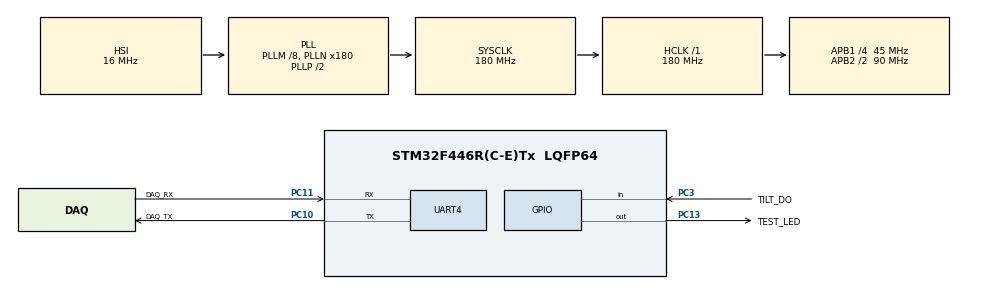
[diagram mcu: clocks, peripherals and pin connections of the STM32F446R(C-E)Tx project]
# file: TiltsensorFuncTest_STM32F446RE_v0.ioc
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Mcu.Family=STM32F4
Mcu.Name=STM32F446R(C-E)Tx
Mcu.Package=LQFP64
NVIC.PriorityGroup=NVIC_PRIORITYGROUP_4
PC10.GPIO_Label=DAQ_TX
PC10.Mode=Asynchronous
PC10.Signal=UART4_TX
PC11.GPIO_Label=DAQ_RX
PC11.Mode=Asynchronous
PC11.Signal=UART4_RX
PC13.GPIO_Label=TEST_LED
PC13.GPIO_PuPd=GPIO_PULLDOWN
PC13.Signal=GPIO_Output
PC14-OSC32_IN.Mode=LSE-External-Oscillator
PC14-OSC32_IN.Signal=RCC_OSC32_IN
PC15-OSC32_OUT.Mode=LSE-External-Oscillator
PC15-OSC32_OUT.Signal=RCC_OSC32_OUT
PC3.GPIO_Label=TILT_DO
PC3.Signal=GPIO_Input
PH0-OSC_IN.Mode=HSE-External-Oscillator
PH0-OSC_IN.Signal=RCC_OSC_IN
PH1-OSC_OUT.Mode=HSE-External-Oscillator
PH1-OSC_OUT.Signal=RCC_OSC_OUT
ProjectManager.HeapSize=0x200
ProjectManager.StackSize=0x400
ProjectManager.TargetToolchain=STM32CubeIDE
RCC.AHBFreq_Value=180000000
RCC.APB1CLKDivider=RCC_HCLK_DIV4
RCC.APB1Freq_Value=45000000
RCC.APB1TimFreq_Value=90000000
RCC.APB2CLKDivider=RCC_HCLK_DIV2
RCC.APB2Freq_Value=90000000
RCC.APB2TimFreq_Value=180000000
RCC.CortexFreq_Value=180000000
RCC.HCLKFreq_Value=180000000
RCC.PLLM=8
RCC.PLLN=180
RCC.SYSCLKFreq_VALUE=180000000
RCC.SYSCLKSource=RCC_SYSCLKSOURCE_PLLCLK
RCC.USBFreq_Value=180000000
RCC.VCOOutputFreq_Value=360000000
UART4.VirtualMode=Asynchronous
board=custom

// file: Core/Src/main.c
/* USER CODE BEGIN Header */
/**
  ******************************************************************************
  * @file           : main.c
  * @brief          : Main program body
  ******************************************************************************
  * @attention
  *
  * Copyright (c) 2024 STMicroelectronics.
  * All rights reserved.
  *
  * This software is licensed under terms that can be found in the LICENSE file
  * in the root directory of this software component.
  * If no LICENSE file comes with this software, it is provided AS-IS.
  *
  ******************************************************************************
  */
/* USER CODE END Header */
#include "main.h"

/* USER CODE BEGIN Includes */
#include "stdbool.h"
#include "string.h"
/* USER CODE END Includes */

UART_HandleTypeDef huart4;

/* USER CODE BEGIN PV */
bool tilt_state = 0;
/* USER CODE END PV */

void SystemClock_Config(void);
static void MX_GPIO_Init(void);
static void MX_UART4_Init(void);

int main(void)
{

  /* MCU Configuration--------------------------------------------------------*/

  /* Reset of all peripherals, Initializes the Flash interface and the Systick. */
  HAL_Init();

  /* Configure the system clock */
  SystemClock_Config();

  /* Initialize all configured peripherals */
  MX_GPIO_Init();
  MX_UART4_Init();

  /* Infinite loop */
  while (1)
  {

    /* USER CODE BEGIN 3 */
	  tilt_state = !HAL_GPIO_ReadPin(TILT_DO_GPIO_Port, TILT_DO_Pin);
	  if(tilt_state)
		  HAL_GPIO_WritePin(TEST_LED_GPIO_Port, TEST_LED_Pin, 1);
	  else
		  HAL_GPIO_WritePin(TEST_LED_GPIO_Port, TEST_LED_Pin, 1);

	  char buffer[10]={0};
	  memcpy(&buffer,&tilt_state,1);
	  HAL_UART_Transmit(&huart4, &buffer, 1, 100);
	  HAL_Delay(10);
  }
  /* USER CODE END 3 */
}

void SystemClock_Config(void)
{
  RCC_OscInitTypeDef RCC_OscInitStruct = {0};
  RCC_ClkInitTypeDef RCC_ClkInitStruct = {0};

  /** Configure the main internal regulator output voltage
  */
  __HAL_RCC_PWR_CLK_ENABLE();
  __HAL_PWR_VOLTAGESCALING_CONFIG(PWR_REGULATOR_VOLTAGE_SCALE1);

  /** Initializes the RCC Oscillators according to the specified parameters
  * in the RCC_OscInitTypeDef structure.
  */
  RCC_OscInitStruct.OscillatorType = RCC_OSCILLATORTYPE_HSI;
  RCC_OscInitStruct.HSIState = RCC_HSI_ON;
  RCC_OscInitStruct.HSICalibrationValue = RCC_HSICALIBRATION_DEFAULT;
  RCC_OscInitStruct.PLL.PLLState = RCC_PLL_ON;
  RCC_OscInitStruct.PLL.PLLSource = RCC_PLLSOURCE_HSI;
  RCC_OscInitStruct.PLL.PLLM = 8;
  RCC_OscInitStruct.PLL.PLLN = 180;
  RCC_OscInitStruct.PLL.PLLP = RCC_PLLP_DIV2;
  RCC_OscInitStruct.PLL.PLLQ = 2;
  RCC_OscInitStruct.PLL.PLLR = 2;
  if (HAL_RCC_OscConfig(&RCC_OscInitStruct) != HAL_OK)
  {
    Error_Handler();
  }

  /** Activate the Over-Drive mode
  */
  if (HAL_PWREx_EnableOverDrive() != HAL_OK)
  {
    Error_Handler();
  }

  /** Initializes the CPU, AHB and APB buses clocks
  */
  RCC_ClkInitStruct.ClockType = RCC_CLOCKTYPE_HCLK|RCC_CLOCKTYPE_SYSCLK
                              |RCC_CLOCKTYPE_PCLK1|RCC_CLOCKTYPE_PCLK2;
  RCC_ClkInitStruct.SYSCLKSource = RCC_SYSCLKSOURCE_PLLCLK;
  RCC_ClkInitStruct.AHBCLKDivider = RCC_SYSCLK_DIV1;
  RCC_ClkInitStruct.APB1CLKDivider = RCC_HCLK_DIV4;
  RCC_ClkInitStruct.APB2CLKDivider = RCC_HCLK_DIV2;

  if (HAL_RCC_ClockConfig(&RCC_ClkInitStruct, FLASH_LATENCY_5) != HAL_OK)
  {
    Error_Handler();
  }
}

static void MX_UART4_Init(void)
{

  huart4.Instance = UART4;
  huart4.Init.BaudRate = 115200;
  huart4.Init.WordLength = UART_WORDLENGTH_8B;
  huart4.Init.StopBits = UART_STOPBITS_1;
  huart4.Init.Parity = UART_PARITY_NONE;
  huart4.Init.Mode = UART_MODE_TX_RX;
  huart4.Init.HwFlowCtl = UART_HWCONTROL_NONE;
  huart4.Init.OverSampling = UART_OVERSAMPLING_16;
  if (HAL_UART_Init(&huart4) != HAL_OK)
  {
    Error_Handler();
  }

}

static void MX_GPIO_Init(void)
{
  GPIO_InitTypeDef GPIO_InitStruct = {0};

  /* GPIO Ports Clock Enable */
  __HAL_RCC_GPIOC_CLK_ENABLE();
  __HAL_RCC_GPIOH_CLK_ENABLE();

  /*Configure GPIO pin Output Level */
  HAL_GPIO_WritePin(TEST_LED_GPIO_Port, TEST_LED_Pin, GPIO_PIN_RESET);

  /*Configure GPIO pin : TEST_LED_Pin */
  GPIO_InitStruct.Pin = TEST_LED_Pin;
  GPIO_InitStruct.Mode = GPIO_MODE_OUTPUT_PP;
  GPIO_InitStruct.Pull = GPIO_PULLDOWN;
  GPIO_InitStruct.Speed = GPIO_SPEED_FREQ_LOW;
  HAL_GPIO_Init(TEST_LED_GPIO_Port, &GPIO_InitStruct);

  /*Configure GPIO pin : TILT_DO_Pin */
  GPIO_InitStruct.Pin = TILT_DO_Pin;
  GPIO_InitStruct.Mode = GPIO_MODE_INPUT;
  GPIO_InitStruct.Pull = GPIO_NOPULL;
  HAL_GPIO_Init(TILT_DO_GPIO_Port, &GPIO_InitStruct);

}

void Error_Handler(void)
{
  __disable_irq();
  while (1)
  {
  }
}
